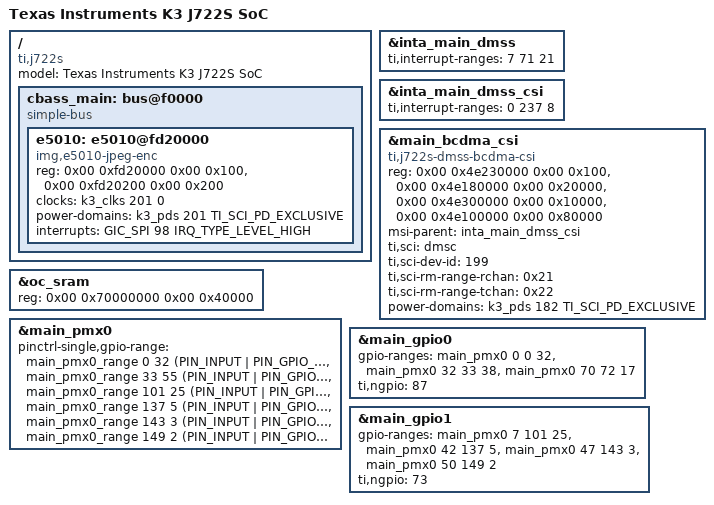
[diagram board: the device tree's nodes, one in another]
// SPDX-License-Identifier: GPL-2.0-only OR MIT
/*
 * Device Tree Source for J722S SoC Family
 *
 * Copyright (C) 2024 Texas Instruments Incorporated - https://www.ti.com/
 */

#include <dt-bindings/gpio/gpio.h>
#include <dt-bindings/interrupt-controller/irq.h>
#include <dt-bindings/interrupt-controller/arm-gic.h>
#include <dt-bindings/soc/ti,sci_pm_domain.h>

#include "k3-am62p5.dtsi"

/ {
	model = "Texas Instruments K3 J722S SoC";
	compatible = "ti,j722s";

	cbass_main: bus@f0000 {
		compatible = "simple-bus";
		#address-cells = <2>;
		#size-cells = <2>;

		ranges = <0x00 0x000f0000 0x00 0x000f0000 0x00 0x00030000>, /* Main MMRs */
			 <0x00 0x00420000 0x00 0x00420000 0x00 0x00001000>, /* ESM0 */
			 <0x00 0x00600000 0x00 0x00600000 0x00 0x00001100>, /* GPIO */
			 <0x00 0x00703000 0x00 0x00703000 0x00 0x00000200>, /* USB0 debug trace */
			 <0x00 0x0070c000 0x00 0x0070c000 0x00 0x00000200>, /* USB1 debug trace */
			 <0x00 0x00a40000 0x00 0x00a40000 0x00 0x00000800>, /* Timesync router */
			 <0x00 0x01000000 0x00 0x01000000 0x00 0x01b28400>, /* First peripheral window */
			 <0x00 0x08000000 0x00 0x08000000 0x00 0x00200000>, /* Main CPSW */
			 <0x00 0x0d000000 0x00 0x0d000000 0x00 0x00800000>, /* PCIE_0 */
			 <0x00 0x0e000000 0x00 0x0e000000 0x00 0x01d20000>, /* Second peripheral window */
			 <0x00 0x0fd80000 0x00 0x0fd80000 0x00 0x00080000>, /* GPU */
			 <0x00 0x0fd20000 0x00 0x0fd20000 0x00 0x00000100>, /* JPEGENC0_CORE */
			 <0x00 0x0fd20200 0x00 0x0fd20200 0x00 0x00000200>, /* JPEGENC0_CORE_MMU */
			 <0x00 0x20000000 0x00 0x20000000 0x00 0x0a008000>, /* Third peripheral window */
			 <0x00 0x30040000 0x00 0x30040000 0x00 0x00080000>, /* PRUSS-M */
			 <0x00 0x301C0000 0x00 0x301C0000 0x00 0x00001000>, /* DPHY-TX */
			 <0x00 0x30101000 0x00 0x30101000 0x00 0x00080100>, /* CSI window */
			 <0x00 0x30200000 0x00 0x30200000 0x00 0x00010000>, /* DSS */
			 <0x00 0x30210000 0x00 0x30210000 0x00 0x00010000>, /* VPU */
			 <0x00 0x30220000 0x00 0x30220000 0x00 0x00010000>, /* DSS1 */
			 <0x00 0x30270000 0x00 0x30270000 0x00 0x00010000>, /* DSI-base1 */
			 <0x00 0x30300000 0x00 0x30300000 0x00 0x00001000>, /* MCRC64 */
			 <0x00 0x30500000 0x00 0x30500000 0x00 0x00100000>, /* DSI-base2 */
			 <0x00 0x31000000 0x00 0x31000000 0x00 0x00050000>, /* USB0 DWC3 Core window */
			 <0x00 0x31200000 0x00 0x31200000 0x00 0x00040000>, /* USB1 DWC3 Core window */
			 <0x00 0x40900000 0x00 0x40900000 0x00 0x00030000>, /* SA3UL */
			 <0x00 0x43600000 0x00 0x43600000 0x00 0x00010000>, /* SA3 sproxy data */
			 <0x00 0x44043000 0x00 0x44043000 0x00 0x00000fe0>, /* TI SCI DEBUG */
			 <0x00 0x44860000 0x00 0x44860000 0x00 0x00040000>, /* SA3 sproxy config */
			 <0x00 0x48000000 0x00 0x48000000 0x00 0x06408000>, /* DMSS */
			 <0x00 0x60000000 0x00 0x60000000 0x00 0x08000000>, /* FSS0 DAT1 */
			 <0x00 0x68000000 0x00 0x68000000 0x00 0x08000000>, /* PCIe0 DAT0 */
			 <0x00 0x70000000 0x00 0x70000000 0x00 0x00040000>, /* OCSRAM */
			 <0x00 0x78400000 0x00 0x78400000 0x00 0x00008000>, /* MAIN R5FSS0 ATCM */
			 <0x00 0x78500000 0x00 0x78500000 0x00 0x00008000>, /* MAIN R5FSS0 BTCM */
			 <0x00 0x7e000000 0x00 0x7e000000 0x00 0x00200000>, /* C7X_0 L2SRAM */
			 <0x00 0x7e200000 0x00 0x7e200000 0x00 0x00200000>, /* C7X_1 L2SRAM */
			 <0x01 0x00000000 0x01 0x00000000 0x00 0x00310000>, /* A53 PERIPHBASE */
			 <0x05 0x00000000 0x05 0x00000000 0x01 0x00000000>, /* FSS0 DAT3 */
			 <0x06 0x00000000 0x06 0x00000000 0x01 0x00000000>, /* PCIe0 DAT1 */

			 /* MCU Domain Range */
			 <0x00 0x04000000 0x00 0x04000000 0x00 0x01ff1400>,
			 <0x00 0x79000000 0x00 0x79000000 0x00 0x00008000>,
			 <0x00 0x79020000 0x00 0x79020000 0x00 0x00008000>,
			 <0x00 0x79100000 0x00 0x79100000 0x00 0x00040000>,
			 <0x00 0x79140000 0x00 0x79140000 0x00 0x00040000>,

			 /* Wakeup Domain Range */
			 <0x00 0x00b00000 0x00 0x00b00000 0x00 0x00002400>,
			 <0x00 0x2b000000 0x00 0x2b000000 0x00 0x00300400>,
			 <0x00 0x43000000 0x00 0x43000000 0x00 0x00020000>,
			 <0x00 0x78000000 0x00 0x78000000 0x00 0x00008000>,
			 <0x00 0x78100000 0x00 0x78100000 0x00 0x00008000>;
	};
};

/* Main domain overrides */

&inta_main_dmss {
	ti,interrupt-ranges = <7 71 21>;
};

&inta_main_dmss_csi {
	ti,interrupt-ranges = <0 237 8>;
};

&main_bcdma_csi {
	compatible = "ti,j722s-dmss-bcdma-csi";
	reg = <0x00 0x4e230000 0x00 0x100>,
	      <0x00 0x4e180000 0x00 0x20000>,
	      <0x00 0x4e300000 0x00 0x10000>,
	      <0x00 0x4e100000 0x00 0x80000>;
	reg-names = "gcfg", "rchanrt", "tchanrt", "ringrt";
	msi-parent = <&inta_main_dmss_csi>;
	#dma-cells = <3>;
	ti,sci = <&dmsc>;
	ti,sci-dev-id = <199>;
	ti,sci-rm-range-rchan = <0x21>;
	ti,sci-rm-range-tchan = <0x22>;
	power-domains = <&k3_pds 182 TI_SCI_PD_EXCLUSIVE>;
};

&oc_sram {
	reg = <0x00 0x70000000 0x00 0x40000>;
	ranges = <0x00 0x00 0x70000000 0x40000>;
};

&main_pmx0 {
	pinctrl-single,gpio-range =
		<&main_pmx0_range 0 32 (PIN_INPUT | PIN_GPIO_MUX_MODE)>,
		<&main_pmx0_range 33 55 (PIN_INPUT | PIN_GPIO_MUX_MODE)>,
		<&main_pmx0_range 101 25 (PIN_INPUT | PIN_GPIO_MUX_MODE)>,
		<&main_pmx0_range 137 5 (PIN_INPUT | PIN_GPIO_MUX_MODE)>,
		<&main_pmx0_range 143 3 (PIN_INPUT | PIN_GPIO_MUX_MODE)>,
		<&main_pmx0_range 149 2 (PIN_INPUT | PIN_GPIO_MUX_MODE)>;
};

&main_gpio0 {
	gpio-ranges = <&main_pmx0 0 0 32>,
		      <&main_pmx0 32 33 38>,
		      <&main_pmx0 70 72 17>;
	ti,ngpio = <87>;
};

&main_gpio1 {
	gpio-ranges = <&main_pmx0 7 101 25>,
		      <&main_pmx0 42 137 5>,
		      <&main_pmx0 47 143 3>,
		      <&main_pmx0 50 149 2>;
	ti,ngpio = <73>;
};

&cbass_main {
	e5010: e5010@fd20000 {
		compatible = "img,e5010-jpeg-enc";
		reg = <0x00 0xfd20000 0x00 0x100>,
		      <0x00 0xfd20200 0x00 0x200>;
		reg-names = "core", "mmu";
		clocks = <&k3_clks 201 0>;
		clock-names = "core_clk";
		power-domains = <&k3_pds 201 TI_SCI_PD_EXCLUSIVE>;
		interrupts = <GIC_SPI 98 IRQ_TYPE_LEVEL_HIGH>;
	};

};

/* Include bus peripherals that are additionally
 * present in J722S
 */
 #include "k3-j722s-main.dtsi"
